# Z20K14xM register map
Vendor: Zhixin Semiconductor; Series: Z20K14xM; File version: 0.1.0
CPU: CM4 r0p1, little endian, no MPU, FPU, 4 interrupt priority bits
Registers are 32-bit, read-write, reset 0x0 unless marked. A register's access mark holds for its fields unless they carry their own. Offsets are from the block's base; [hi:lo] are bit positions.

## I2C1
Base 0x40058000
0x00 I2C1_I2C_VERID reset 0x6060606 — I2C Version ID(I2C_VERID)
  [31:0] VERID — version ID
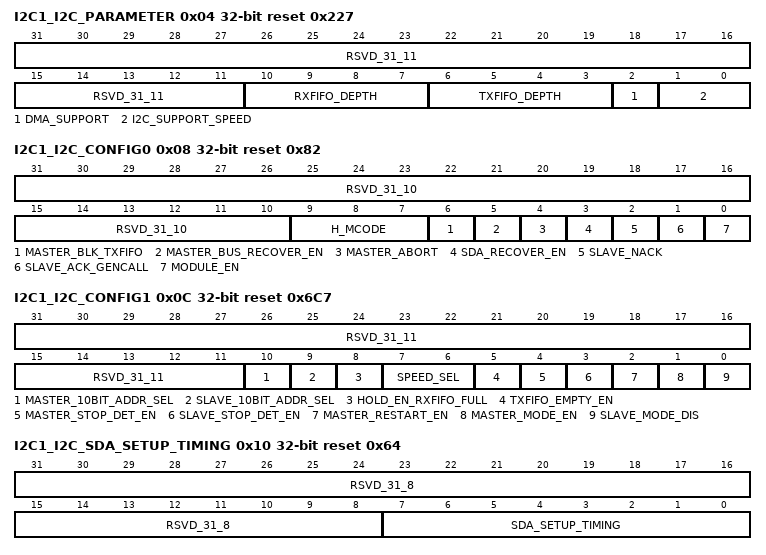
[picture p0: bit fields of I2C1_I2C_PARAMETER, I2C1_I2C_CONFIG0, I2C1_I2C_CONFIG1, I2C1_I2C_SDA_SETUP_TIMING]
0x04 I2C1_I2C_PARAMETER reset 0x227 — I2C Parameter Register(I2C_PARAMETER)
  [31:11] RSVD_31_11 — reserve
  [10:7] RXFIFO_DEPTH
  [6:3] TXFIFO_DEPTH
  [2] DMA_SUPPORT — DMA support bit
  [1:0] I2C_SUPPORT_SPEED — I2C transfer speed supported
0x08 I2C1_I2C_CONFIG0 reset 0x82 — I2C Configure0 Register(I2C_CONFIG0)
  [31:10] RSVD_31_10 — reserve
  [9:7] H_MCODE — high speed master code
  [6] MASTER_BLK_TXFIFO — block master TX FIFO transfer
  [5] MASTER_BUS_RECOVER_EN — enable I2C master bus recover feature
  [4] MASTER_ABORT — master abort transfer bit
  [3] SDA_RECOVER_EN — SDA recover feature enable
  [2] SLAVE_NACK — slave nack bit
  [1] SLAVE_ACK_GENCALL — slave general call ack
  [0] MODULE_EN — module enable bit
0x0C I2C1_I2C_CONFIG1 reset 0x6C7 — I2C Configure1 Register(I2C_CONFIG1)
  [31:11] RSVD_31_11 — reserve
  [10] MASTER_10BIT_ADDR_SEL — master 10bit address mode select
  [9] SLAVE_10BIT_ADDR_SEL — slave 10bit address mode select
  [8] HOLD_EN_RXFIFO_FULL — hold I2C bus feature enable when RXFIFO is full.
  [7:6] SPEED_SEL — I2C speed select
  [5] TXFIFO_EMPTY_EN — allow generate TXFIFO empty flag.
  [4] MASTER_STOP_DET_EN — stop detect feature enable during master mode
  [3] SLAVE_STOP_DET_EN — stop detect feature enable during slave mode
  [2] MASTER_RESTART_EN — enable restart feature during master mode
  [1] MASTER_MODE_EN — master mode enable
  [0] SLAVE_MODE_DIS — slave mode disable
0x10 I2C1_I2C_SDA_SETUP_TIMING reset 0x64 — I2C SDA Setup Timing Register(I2C_SDA_SETUP_TIMING)
  [31:8] RSVD_31_8 — reserve
  [7:0] SDA_SETUP_TIMING — SDA setup timing value
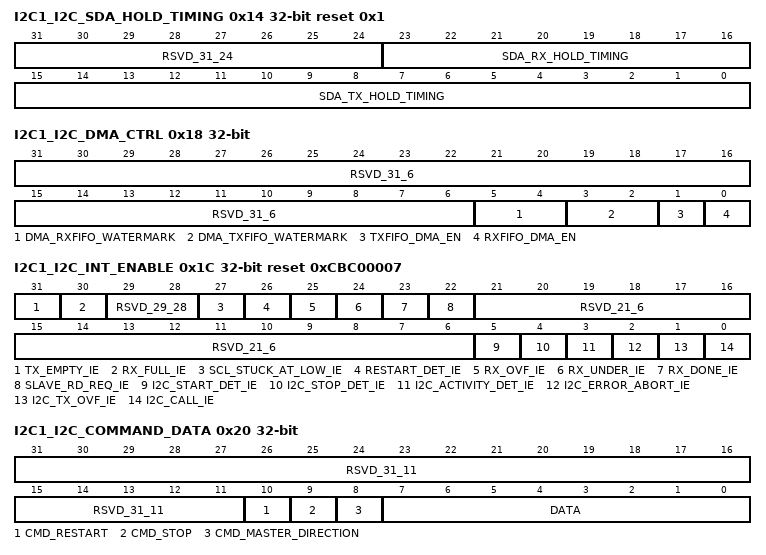
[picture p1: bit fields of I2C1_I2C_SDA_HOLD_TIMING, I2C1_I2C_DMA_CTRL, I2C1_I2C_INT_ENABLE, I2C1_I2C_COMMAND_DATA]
0x14 I2C1_I2C_SDA_HOLD_TIMING reset 0x1 — I2C SDA Hold Timing Register(I2C_SDA_HOLD_TIMING)
  [31:24] RSVD_31_24 — reserve
  [23:16] SDA_RX_HOLD_TIMING — SDA RX hold timing value
  [15:0] SDA_TX_HOLD_TIMING — SDA TX hold timing value
0x18 I2C1_I2C_DMA_CTRL — I2C DMA Control Register(I2C_DMA_CTRL)
  [31:6] RSVD_31_6 — reserve
  [5:4] DMA_RXFIFO_WATERMARK
  [3:2] DMA_TXFIFO_WATERMARK
  [1] TXFIFO_DMA_EN — TXFIFO DMA enable
  [0] RXFIFO_DMA_EN — RXFIFO DMA enable
0x1C I2C1_I2C_INT_ENABLE reset 0xCBC00007 — I2C Interrupt Enable Register(I2C_INT_ENABLE)
  [31] TX_EMPTY_IE — TXFIFO interrupt enable
  [30] RX_FULL_IE — RXFIFO interrupt enable
  [29:28] RSVD_29_28 — reserve
  [27] SCL_STUCK_AT_LOW_IE — SCL stuck at low interrupt enable
  [26] RESTART_DET_IE — restart detect interrupt enable
  [25] RX_OVF_IE — RX overun interrupt enable
  [24] RX_UNDER_IE — RX under interrupt enable
  [23] RX_DONE_IE — RX done interrupt enable
  [22] SLAVE_RD_REQ_IE — slave read request interrupt enable
  [21:6] RSVD_21_6 — reserve
  [5] I2C_START_DET_IE — I2C start detect interrupt enable
  [4] I2C_STOP_DET_IE — I2C stop detect interrupt enable
  [3] I2C_ACTIVITY_DET_IE — I2C activity detect interrupt enable
  [2] I2C_ERROR_ABORT_IE — I2C Error abort interrupt enable
  [1] I2C_TX_OVF_IE — I2C TX overun interrupt enable
  [0] I2C_CALL_IE — I2C general call interrupt enable
0x20 I2C1_I2C_COMMAND_DATA — I2C Rx/Tx Data Buffer and Command Register(I2C_COMMAND_DATA)
  [31:11] RSVD_31_11 — reserve
  [10] CMD_RESTART — command restart
  [9] CMD_STOP — command stop
  [8] CMD_MASTER_DIRECTION — command direction
  [7:0] DATA
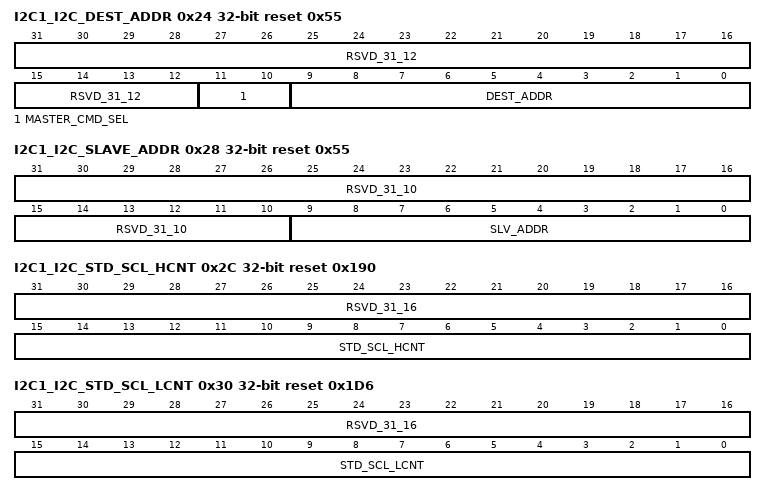
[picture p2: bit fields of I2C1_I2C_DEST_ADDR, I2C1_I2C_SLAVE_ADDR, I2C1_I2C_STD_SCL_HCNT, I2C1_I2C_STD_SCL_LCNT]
0x24 I2C1_I2C_DEST_ADDR reset 0x55 — I2C Target Address Register(I2C_DEST_ADDR)
  [31:12] RSVD_31_12 — reserve
  [11:10] MASTER_CMD_SEL — master command select
  [9:0] DEST_ADDR — destination addresss
0x28 I2C1_I2C_SLAVE_ADDR reset 0x55 — I2C Slave Address Register(I2C_SLAVE_ADDR)
  [31:10] RSVD_31_10 — reserve
  [9:0] SLV_ADDR — slave address
0x2C I2C1_I2C_STD_SCL_HCNT reset 0x190 — Standard Speed I2C SCL High Count register(I2C_STD_SCL_HCNT)
  [31:16] RSVD_31_16 — reserve
  [15:0] STD_SCL_HCNT — standard SCL high counter value
0x30 I2C1_I2C_STD_SCL_LCNT reset 0x1D6 — Standard Speed I2C SCL Low Count Register(I2C_STD_SCL_LCNT)
  [31:16] RSVD_31_16 — reserve
  [15:0] STD_SCL_LCNT — standard SCL low counter value
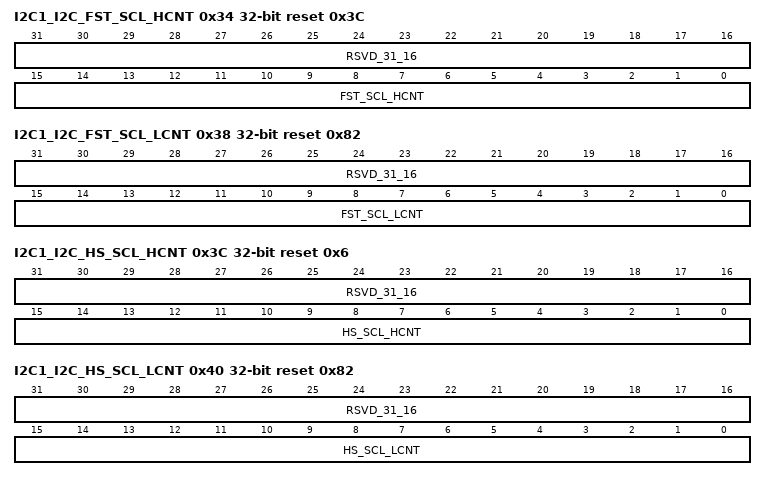
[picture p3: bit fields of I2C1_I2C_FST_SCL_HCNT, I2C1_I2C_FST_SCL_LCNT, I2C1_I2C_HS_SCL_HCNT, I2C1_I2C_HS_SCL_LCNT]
0x34 I2C1_I2C_FST_SCL_HCNT reset 0x3C — Fast Mode I2C SCL High Count Register(I2C_FST_SCL_HCNT)
  [31:16] RSVD_31_16 — reserve
  [15:0] FST_SCL_HCNT — Fast SCL high counter value
0x38 I2C1_I2C_FST_SCL_LCNT reset 0x82 — Fast Mode I2C SCL Low Count Register(I2C_FST_SCL_LCNT)
  [31:16] RSVD_31_16 — reserve
  [15:0] FST_SCL_LCNT — Fast SCL low counter value
0x3C I2C1_I2C_HS_SCL_HCNT reset 0x6 — High Speed I2C SCL High Count Register(2C_HS_SCL_HCNT)
  [31:16] RSVD_31_16 — reserve
  [15:0] HS_SCL_HCNT — High speed SCL high counter value
0x40 I2C1_I2C_HS_SCL_LCNT reset 0x82 — High Speed I2C SCL Low Count Register(I2C_HS_SCL_LCNT)
  [31:16] RSVD_31_16 — reserve
  [15:0] HS_SCL_LCNT — High speed SCL low counter value
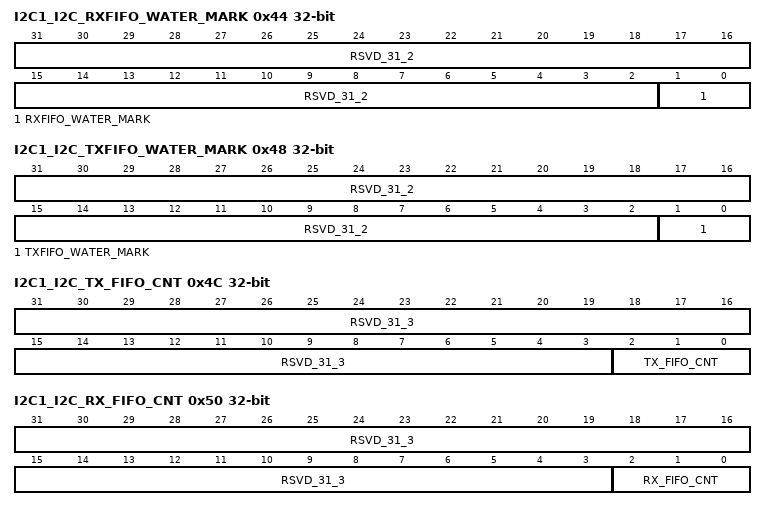
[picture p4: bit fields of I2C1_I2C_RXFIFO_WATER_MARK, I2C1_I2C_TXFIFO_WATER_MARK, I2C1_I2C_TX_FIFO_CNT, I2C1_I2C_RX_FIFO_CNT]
0x44 I2C1_I2C_RXFIFO_WATER_MARK — I2C Receive FIFO Water Mark Register(I2C_RXFIFO_WATER_MARK)
  [31:2] RSVD_31_2 — reserve
  [1:0] RXFIFO_WATER_MARK
0x48 I2C1_I2C_TXFIFO_WATER_MARK — I2C Transmit FIFO Water Mark Register(I2C_TXFIFO_WATER_MARK)
  [31:2] RSVD_31_2 — reserve
  [1:0] TXFIFO_WATER_MARK
0x4C I2C1_I2C_TX_FIFO_CNT — I2C Transmit FIFO Valid Entry Counter Register(I2C_TX_FIFO_CNT)
  [31:3] RSVD_31_3 — reserve
  [2:0] TX_FIFO_CNT — TX FIFO valid entries
0x50 I2C1_I2C_RX_FIFO_CNT — I2C Receive FIFO Valid Entry Counter Register(I2C_RX_FIFO_CNT)
  [31:3] RSVD_31_3 — reserve
  [2:0] RX_FIFO_CNT — RX FIFO valid entries
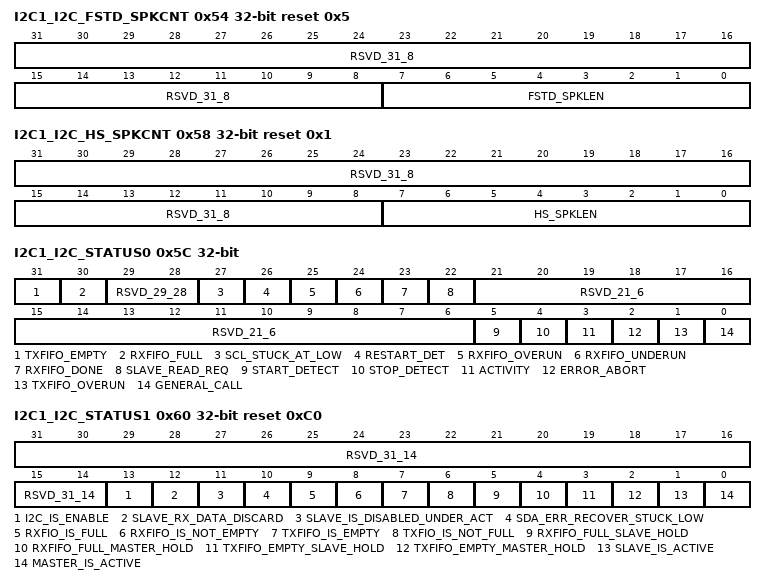
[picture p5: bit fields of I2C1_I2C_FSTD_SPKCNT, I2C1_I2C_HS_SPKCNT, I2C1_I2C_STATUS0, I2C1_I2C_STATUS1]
0x54 I2C1_I2C_FSTD_SPKCNT reset 0x5 — I2C Fast and Standard Spike Suppression Limit Register(I2C_FSTD_SPKCNT)
  [31:8] RSVD_31_8 — reserve
  [7:0] FSTD_SPKLEN — fast and standard spike counter length
0x58 I2C1_I2C_HS_SPKCNT reset 0x1 — I2C High Speed Spike Suppression Limit Register(I2C_HS_SPKCNT)
  [31:8] RSVD_31_8 — reserve
  [7:0] HS_SPKLEN — High speed spike counter
0x5C I2C1_I2C_STATUS0 — I2C Interrupt Status Register(I2C_STATUS0)
  [31] TXFIFO_EMPTY — TXFIFO empty flag
  [30] RXFIFO_FULL — RXFIFO full flag
  [29:28] RSVD_29_28 — reserve
  [27] SCL_STUCK_AT_LOW — SCL stuck at low flag
  [26] RESTART_DET — restart detect flag
  [25] RXFIFO_OVERUN — RXFIFO overun flag
  [24] RXFIFO_UNDERUN — RXFIFO underun flag
  [23] RXFIFO_DONE — RX FIFO done flag
  [22] SLAVE_READ_REQ — RXFIFO slave read request flag
  [21:6] RSVD_21_6 — reserve
  [5] START_DETECT — start detect flag
  [4] STOP_DETECT — stop detect flag
  [3] ACTIVITY — I2C activity flag
  [2] ERROR_ABORT — transfer abort flag
  [1] TXFIFO_OVERUN — TXFIFO overrun flag
  [0] GENERAL_CALL — general call flag
0x60 I2C1_I2C_STATUS1 reset 0xC0 — I2C Status Register(I2C_STATUS1)
  [31:14] RSVD_31_14 — reserve
  [13] I2C_IS_ENABLE — I2C is enabled flag
  [12] SLAVE_RX_DATA_DISCARD — slave receive data discard flag.
  [11] SLAVE_IS_DISABLED_UNDER_ACT — slave disabled under active
  [10] SDA_ERR_RECOVER_STUCK_LOW — SDA error recover from stucking at low flag.
  [9] RXFIO_IS_FULL — RXFIFO full flag
  [8] RXFIFO_IS_NOT_EMPTY — RXFIFO is not empty flag.
  [7] TXFIFO_IS_EMPTY — TXFIFO is empty flag.
  [6] TXFIO_IS_NOT_FULL — TXFIFO is not full flag.
  [5] RXFIFO_FULL_SLAVE_HOLD — slave RXFIFO hold bus when RXFIFO full
  [4] RXFIFO_FULL_MASTER_HOLD — master RXFIFO hold bus when RXFIFO full
  [3] TXFIFO_EMPTY_SLAVE_HOLD — slave hold bus when TXFIFO empty
  [2] TXFIFO_EMPTY_MASTER_HOLD — master hold bus when TXFIFO empty
  [1] SLAVE_IS_ACTIVE — slave is active flag
  [0] MASTER_IS_ACTIVE — master is active flag
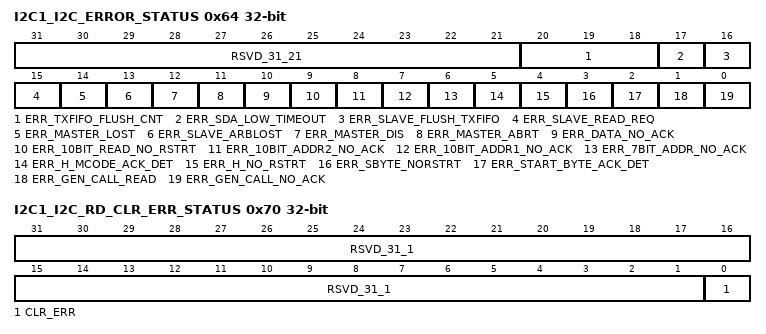
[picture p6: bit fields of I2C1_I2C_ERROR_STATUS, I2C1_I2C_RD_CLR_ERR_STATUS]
0x64 I2C1_I2C_ERROR_STATUS — I2C Error Status Register(I2C_ERROR_STATUS)
  [31:21] RSVD_31_21 — reserve
  [20:18] ERR_TXFIFO_FLUSH_CNT — error counter of TXFIFO flush
  [17] ERR_SDA_LOW_TIMEOUT — error flag of SDA stuck low timeout
  [16] ERR_SLAVE_FLUSH_TXFIFO — error flag of slave flush TXFIFO
  [15] ERR_SLAVE_READ_REQ — error flag of slave read request
  [14] ERR_MASTER_LOST — error flag of master lost
  [13] ERR_SLAVE_ARBLOST — error flag of slave lost
  [12] ERR_MASTER_DIS — error flag of master disable
  [11] ERR_MASTER_ABRT — error flag of master abort
  [10] ERR_DATA_NO_ACK — error flag of master data no_ack
  [9] ERR_10BIT_READ_NO_RSTRT — error flag of 10bit read under restart_en=0
  [8] ERR_10BIT_ADDR2_NO_ACK — error flag of 10bit second address no ack
  [7] ERR_10BIT_ADDR1_NO_ACK — error flag of 10bit first address no ack
  [6] ERR_7BIT_ADDR_NO_ACK — error flag of 7bit address no ack
  [5] ERR_H_MCODE_ACK_DET — error flag of high speed master code ack
  [4] ERR_H_NO_RSTRT — error flag of high speed under restart_en=0
  [3] ERR_SBYTE_NORSTRT — error flag of sending start byte under restart_en=0
  [2] ERR_START_BYTE_ACK_DET — error flag of ack from start byte
  [1] ERR_GEN_CALL_READ — error flag of reading from general call
  [0] ERR_GEN_CALL_NO_ACK — error flag of no ack from general call
0x68 I2C1_I2C_SCL_LOW_TIMEOUT reset 0xFFFFFFFF — I2C SCL Stuck at Low Timeout Register(I2C_SCL_LOW_TIMEOUT)
  [31:0] SCL_LOW_TIMEOUT — SCL stuck at low timeout
0x6C I2C1_I2C_SDA_LOW_TIMEOUT reset 0xFFFFFFFF — I2C SDA Stuck at Low Timeout Register(I2C_SDA_LOW_TIMEOUT)
  [31:0] SDA_LOW_TIMEOUT — SDA stuck at low timeout
0x70 I2C1_I2C_RD_CLR_ERR_STATUS — I2C Read Clear Error Status Register(I2C_RD_CLR_ERR_STATUS)
  [31:1] RSVD_31_1 — reserve
  [0] CLR_ERR — read clear I2C_ERROR_STATUS flags.

## I2C0
Base 0x40066000
Registers as I2C1 (with I2C1 read as I2C0).
